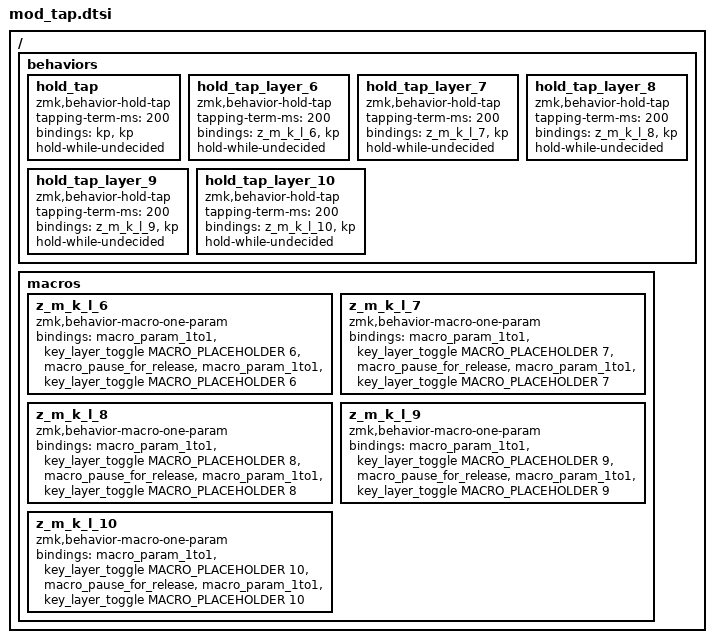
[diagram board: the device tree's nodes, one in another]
/ {
    behaviors {
        // 单击和长按设置不同按键 - 优先触发长按
        hold_tap: hold_tap {
            compatible = "zmk,behavior-hold-tap";
            #binding-cells = <2>;
            tapping-term-ms = <200>;
            bindings = <&kp>, <&kp>;
            hold-while-undecided;
        };

        // 单击触发按键，长按触发另一个按键并换层 - 优先触发长按
        hold_tap_layer_6: hold_tap_layer_6 {
            compatible = "zmk,behavior-hold-tap";
            #binding-cells = <2>;
            tapping-term-ms = <200>;
            bindings = <&z_m_k_l_6>, <&kp>;
            hold-while-undecided;
        };
        hold_tap_layer_7: hold_tap_layer_7 {
            compatible = "zmk,behavior-hold-tap";
            #binding-cells = <2>;
            tapping-term-ms = <200>;
            bindings = <&z_m_k_l_7>, <&kp>;
            hold-while-undecided;
        };
        hold_tap_layer_8: hold_tap_layer_8 {
            compatible = "zmk,behavior-hold-tap";
            #binding-cells = <2>;
            tapping-term-ms = <200>;
            bindings = <&z_m_k_l_8>, <&kp>;
            hold-while-undecided;
        };
        hold_tap_layer_9: hold_tap_layer_9 {
            compatible = "zmk,behavior-hold-tap";
            #binding-cells = <2>;
            tapping-term-ms = <200>;
            bindings = <&z_m_k_l_9>, <&kp>;
            hold-while-undecided;
        };
        hold_tap_layer_10: hold_tap_layer_10 {
            compatible = "zmk,behavior-hold-tap";
            #binding-cells = <2>;
            tapping-term-ms = <200>;
            bindings = <&z_m_k_l_10>, <&kp>;
            hold-while-undecided;
        };
    };

    macros {
        // 同时触发按键和层 - 固定的层，配合hold_tap_layer用
        z_m_k_l_6: z_m_k_l_6{
            compatible = "zmk,behavior-macro-one-param";
            #binding-cells = <1>;
            bindings = 
                <&macro_param_1to1>,
                <&key_layer_toggle MACRO_PLACEHOLDER 6>,
                <&macro_pause_for_release>,
                <&macro_param_1to1>,
                <&key_layer_toggle MACRO_PLACEHOLDER 6>;
        };
        z_m_k_l_7: z_m_k_l_7{
            compatible = "zmk,behavior-macro-one-param";
            #binding-cells = <1>;
            bindings = 
                <&macro_param_1to1>,
                <&key_layer_toggle MACRO_PLACEHOLDER 7>,
                <&macro_pause_for_release>,
                <&macro_param_1to1>,
                <&key_layer_toggle MACRO_PLACEHOLDER 7>;
        };
        z_m_k_l_8: z_m_k_l_8{
            compatible = "zmk,behavior-macro-one-param";
            #binding-cells = <1>;
            bindings = 
                <&macro_param_1to1>,
                <&key_layer_toggle MACRO_PLACEHOLDER 8>,
                <&macro_pause_for_release>,
                <&macro_param_1to1>,
                <&key_layer_toggle MACRO_PLACEHOLDER 8>;
        };
        z_m_k_l_9: z_m_k_l_9{
            compatible = "zmk,behavior-macro-one-param";
            #binding-cells = <1>;
            bindings = 
                <&macro_param_1to1>,
                <&key_layer_toggle MACRO_PLACEHOLDER 9>,
                <&macro_pause_for_release>,
                <&macro_param_1to1>,
                <&key_layer_toggle MACRO_PLACEHOLDER 9>;
        };
        z_m_k_l_10: z_m_k_l_10{
            compatible = "zmk,behavior-macro-one-param";
            #binding-cells = <1>;
            bindings = 
                <&macro_param_1to1>,
                <&key_layer_toggle MACRO_PLACEHOLDER 10>,
                <&macro_pause_for_release>,
                <&macro_param_1to1>,
                <&key_layer_toggle MACRO_PLACEHOLDER 10>;
        };
    };
};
